AUTOSAR XML (schema 4-3-0)
package /ApplicationLayer/CompositionPackage
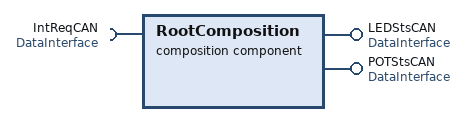
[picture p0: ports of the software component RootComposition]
  composition sw component type RootComposition
    require port IntReqCAN: required-interface=DataInterface
    provide port LEDStsCAN: provided-interface=DataInterface
    provide port POTStsCAN: provided-interface=DataInterface
    6 x component:
      PotSensorInstance: type=PotSensor
      SwtSensorInstance: type=SwtSensor
      RedLiIntControllerInstance: type=IntController
      BlueLiActuatorInstance: type=LEDActuator
      LightManagerInstance: type=LightManager
      IoHwAbInstance: type=IoHwAb
    connect SwtSensorInstance.SwtSts -> LightManagerInstance.BtnPressed
    connect LightManagerInstance.BlueLiSts -> BlueLiActuatorInstance.LightSts
    connect LightManagerInstance.RedLiIntSts -> RedLiIntControllerInstance.IntSts
    connect IoHwAbInstance.Digital_Swt -> SwtSensorInstance.SwtSignal
    connect IoHwAbInstance.Digital_BlueLED -> BlueLiActuatorInstance.LEDSignal
    connect IoHwAbInstance.Pwm_RedLEDDuty -> RedLiIntControllerInstance.DutySignal
    connect IoHwAbInstance.Analog_POT -> PotSensorInstance.POTSignal
    delegate LightManagerInstance.IntReq <-> outer port IntReqCAN
    delegate LightManagerInstance.LEDSts <-> outer port LEDStsCAN
    delegate PotSensorInstance.POTSts <-> outer port POTStsCAN
package /ApplicationLayer/Interface
  impl type IntImpl: category=VALUE, base-type=uint8
  app type Int: category=VALUE
  impl type SwitchStatusImpl: category=BOOLEAN, base-type=boolean
  app type SwitchStatus: category=BOOLEAN
  impl type LEDStatusImpl: category=BOOLEAN, base-type=boolean
  app type LEDStatus: category=BOOLEAN
  impl type IntensityStatusImpl: category=BOOLEAN, base-type=float32
  app type IntensityStatus: category=BOOLEAN
  data type mapping set TypeMappings
    data-type-maps:
      application-data-type=Int, implementation-data-type=IntImpl
      application-data-type=SwitchStatus, implementation-data-type=SwitchStatusImpl
      application-data-type=LEDStatus, implementation-data-type=LEDStatusImpl
      application-data-type=IntensityStatus, implementation-data-type=IntensityStatusImpl
  4 x sender receiver interface:
    DataInterface
      data message: type=Int
    swtInterface
      data status: type=SwitchStatus
    LEDStsInterface
      data status: type=LEDStatus
    IntStsInterface
      data status: type=IntensityStatus
package /ApplicationLayer/EcuExtract
  system MyAUTOSAREcuExtract: category=ECU_EXTRACT, system-version=1
    system mapping ImplementationMappings
      sw-impl-mappings:
        6 x swc to impl mapping:
          SwcToImplMapping_for_PotSensorImpl_to_PotSensorInstance: component-implementation=PotSensorImpl, component=RootSwComposition.PotSensorInstance
          SwcToImplMapping_for_SwtSensorImpl_to_SwtSensorInstance: component-implementation=SwtSensorImpl, component=RootSwComposition.SwtSensorInstance
          SwcToImplMapping_for_IntControllerImpl_to_RedLiIntControllerInstance: component-implementation=IntControllerImpl, component=RootSwComposition.RedLiIntControllerInstance
          SwcToImplMapping_for_LEDActuatorImpl_to_BlueLiActuatorInstance: component-implementation=LEDActuatorImpl, component=RootSwComposition.BlueLiActuatorInstance
          SwcToImplMapping_for_LightManagerImpl_to_LightManagerInstance: component-implementation=LightManagerImpl, component=RootSwComposition.LightManagerInstance
          SwcToImplMapping_for_IoHwAbImpl_to_IoHwAbInstance: component-implementation=IoHwAbImpl, component=RootSwComposition.IoHwAbInstance
    system mapping SignalMappings
      data-mappings:
        data-element=RootSwComposition.POTStsCAN.message, system-signal=PotValue
        data-element=RootSwComposition.LEDStsCAN.message, system-signal=LEDSts
        data-element=RootSwComposition.IntReqCAN.message, system-signal=IntReq
    root-software-compositions:
      root sw composition prototype RootSwComposition: software-composition=RootComposition
package /ApplicationLayer/Signals
  pdu ECU01_01_3FE: unused-bit-pattern=0
    signal ISignalIntReq: 0 bit, data-type-policy=NETWORK-REPRESENTATION-FROM-COM-SPEC
  pdu MyECU_01_3FF: unused-bit-pattern=0
    signal ISignalLEDSts: 0 bit, data-type-policy=NETWORK-REPRESENTATION-FROM-COM-SPEC
    signal ISignalPotValue: 0 bit, data-type-policy=NETWORK-REPRESENTATION-FROM-COM-SPEC
package /ApplicationLayer/ApplicationPackage
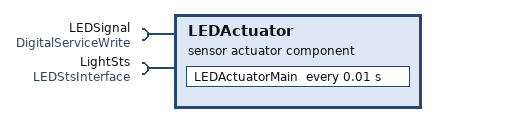
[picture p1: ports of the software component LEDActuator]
  sensor actuator sw component type LEDActuator
    require port LEDSignal: required-interface=DigitalServiceWrite
    require port LightSts: required-interface=LEDStsInterface
    behavior LEDActuatorBehavior: data-type-mapping=TypeMappings, handle-termination-and-restart=NO-SUPPORT
      timing event LEDActuatorMainEvent: start-on-event=LEDActuatorMain, period=0.01
      runnable LEDActuatorMain
        data-read-access:
          access dataReadAccess_LEDActuatorMain_LightSts_status: accessed-variable=LightSts.status
        sync call LEDSignal_Write: operation=LEDSignal.Write, timeout=0.0
  swc implementation LEDActuatorImpl: programming-language=C, vendor-id=0, behavior=LEDActuatorBehavior
    code-descriptors:
      code src: artifact-descriptors=autosar-engineering-object={short-label=artifactDescriptor, category=artifactDescriptorCategory}
    resource consumption resourceConsumption
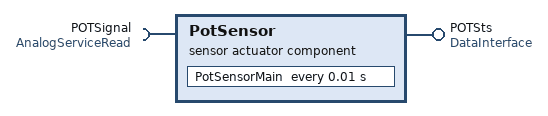
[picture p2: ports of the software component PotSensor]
  sensor actuator sw component type PotSensor
    require port POTSignal: required-interface=AnalogServiceRead
    provide port POTSts: provided-interface=DataInterface
    behavior PotSensorBehavior: data-type-mapping=TypeMappings, handle-termination-and-restart=NO-SUPPORT
      timing event PotSensorMainEvent: start-on-event=PotSensorMain, period=0.01
      runnable PotSensorMain
        data-write-access:
          access dataWriteAccess_PotSensorMain_POTSts_message: accessed-variable=POTSts.message
        sync call POTSignal_Read: operation=POTSignal.Read, timeout=0.0
  swc implementation PotSensorImpl: programming-language=C, vendor-id=0, behavior=PotSensorBehavior
    code-descriptors:
      code src: artifact-descriptors=autosar-engineering-object={short-label=artifactDescriptor, category=artifactDescriptorCategory}
    resource consumption resourceConsumption
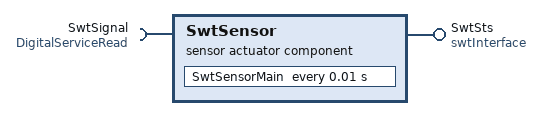
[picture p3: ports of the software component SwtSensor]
  sensor actuator sw component type SwtSensor
    require port SwtSignal: required-interface=DigitalServiceRead
    provide port SwtSts: provided-interface=swtInterface
    behavior SwtSensorBehavior: data-type-mapping=TypeMappings, handle-termination-and-restart=NO-SUPPORT
      timing event SwtSensorMainEvent: start-on-event=SwtSensorMain, period=0.01
      runnable SwtSensorMain
        data-write-access:
          access dataWriteAccess_SwtSensorMain_SwtSts_status: accessed-variable=SwtSts.status
        sync call SwtSignal_Read: operation=SwtSignal.Read, timeout=0.0
  swc implementation SwtSensorImpl: programming-language=C, vendor-id=0, behavior=SwtSensorBehavior
    code-descriptors:
      code src: artifact-descriptors=autosar-engineering-object={short-label=artifactDescriptor, category=artifactDescriptorCategory}
    resource consumption resourceConsumption
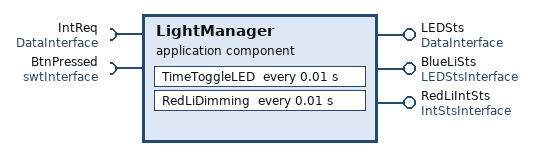
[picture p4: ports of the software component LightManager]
  application sw component type LightManager
    require port IntReq: required-interface=DataInterface
    provide port LEDSts: provided-interface=DataInterface
    require port BtnPressed: required-interface=swtInterface
    provide port BlueLiSts: provided-interface=LEDStsInterface
    provide port RedLiIntSts: provided-interface=IntStsInterface
    behavior LightManagerBehaviour: data-type-mapping=TypeMappings, handle-termination-and-restart=NO-SUPPORT
      timing event TimeToggleLEDEvent: start-on-event=TimeToggleLED, period=0.01
      timing event RedLiDimmingEvent: start-on-event=RedLiDimming, period=0.01
      runnable TimeToggleLED: symbol=TimeToggleLEDMain
        data-read-access:
          access dataReadAccess_TimeToggleLED_BtnPressed_status: accessed-variable=BtnPressed.status
        data-write-access:
          access dataWriteAccess_TimeToggleLED_BlueLiSts_status: accessed-variable=BlueLiSts.status
          access dataWriteAccess_TimeToggleLED_LEDSts_message: accessed-variable=LEDSts.message
      runnable RedLiDimming: symbol=RedLiDimmingMain
        data-read-access:
          access dataReadAccess_RedLiDimming_IntReq_message: accessed-variable=IntReq.message
        data-write-access:
          access dataWriteAccess_RedLiDimming_RedLiIntSts_status: accessed-variable=RedLiIntSts.status
  swc implementation LightManagerImpl: programming-language=C, vendor-id=0, behavior=LightManagerBehaviour
    code-descriptors:
      code src: artifact-descriptors=autosar-engineering-object={short-label=artifactDescriptor, category=artifactDescriptorCategory}
    resource consumption resourceConsumption
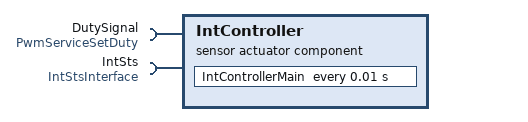
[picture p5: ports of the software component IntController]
  sensor actuator sw component type IntController
    require port DutySignal: required-interface=PwmServiceSetDuty
    require port IntSts: required-interface=IntStsInterface
    behavior IntControllerBehavior: data-type-mapping=TypeMappings, handle-termination-and-restart=NO-SUPPORT
      timing event IntControllerMainEvent: start-on-event=IntControllerMain, period=0.01
      runnable IntControllerMain
        data-read-access:
          access dataReadAccess_IntControllerMain_IntSts_status: accessed-variable=IntSts.status
        sync call DutySignal_Set: operation=DutySignal.Set, timeout=0.0
  swc implementation IntControllerImpl: programming-language=C, vendor-id=0, behavior=IntControllerBehavior
    code-descriptors:
      code src: artifact-descriptors=autosar-engineering-object={short-label=artifactDescriptor, category=artifactDescriptorCategory}
    resource consumption resourceConsumption
package /BSWConfiguration/Services/IoHwAb
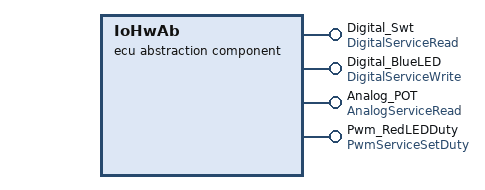
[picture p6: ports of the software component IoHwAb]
  ecu abstraction sw component type IoHwAb
    4 x provide port:
      Digital_Swt: provided-interface=DigitalServiceRead
      Digital_BlueLED: provided-interface=DigitalServiceWrite
      Analog_POT: provided-interface=AnalogServiceRead
      Pwm_RedLEDDuty: provided-interface=PwmServiceSetDuty
    behavior IoHwAbBehavior: handle-termination-and-restart=NO-SUPPORT
      4 x operation invoked event:
        DigitalRead_Digital_Swt_Read: start-on-event=DigitalRead, operation=Digital_Swt.Read
        DigitalWrite_Digital_BlueLED_Write: start-on-event=DigitalWrite, operation=Digital_BlueLED.Write
        AnalogRead_Analog_POT_Read: start-on-event=AnalogRead, operation=Analog_POT.Read
        PwmSetDuty_Pwm_RedLEDDuty_Set: start-on-event=PwmSetDuty, operation=Pwm_RedLEDDuty.Set
      port-api-options:
        {port-defined-argument-value{value=IoHwAb_SignalType_:0, value-type=IoHwAb_SignalType_}, port=Digital_Swt}
        {port-defined-argument-value{value=IoHwAb_SignalType_:1, value-type=IoHwAb_SignalType_}, port=Digital_BlueLED}
        {port-defined-argument-value{value=IoHwAb_SignalType_:0, value-type=IoHwAb_SignalType_}, port=Analog_POT}
        {port-defined-argument-value{value=IoHwAb_SignalType_:0, value-type=IoHwAb_SignalType_}, port=Pwm_RedLEDDuty}
      4 x runnable, all with can-be-invoked-concurrently=true:
        DigitalRead: symbol=IoHwAb_Digital_Read
        DigitalWrite: symbol=IoHwAb_Digital_Write
        AnalogRead: symbol=IoHwAb_Analog_Read
        PwmSetDuty: symbol=IoHwAb_Pwm_Set_Duty
  swc implementation IoHwAbImpl: programming-language=C, vendor-id=60, behavior=IoHwAbBehavior
    code-descriptors:
      code src: artifact-descriptors=autosar-engineering-object={short-label=artifactDescriptor, category=artifactDescriptorCategory}
    resource consumption resourceConsumption
